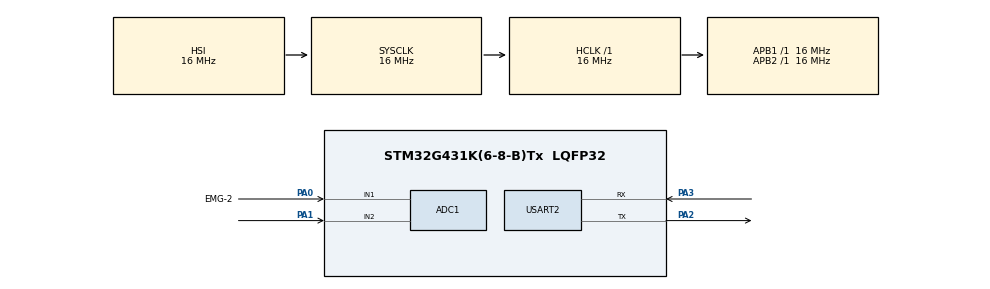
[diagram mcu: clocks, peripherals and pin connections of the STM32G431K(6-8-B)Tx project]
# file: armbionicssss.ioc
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ADC1.Channel-0\#ChannelRegularConversion=ADC_CHANNEL_1
ADC1.Channel-1\#ChannelRegularConversion=ADC_CHANNEL_2
ADC1.ContinuousConvMode=DISABLE
ADC1.DMAContinuousRequests=ENABLE
ADC1.EOCSelection=ADC_EOC_SEQ_CONV
ADC1.ExternalTrigConv=ADC_EXTERNALTRIG_T1_TRGO
ADC1.NbrOfConversion=2
ADC1.NbrOfConversionFlag=1
ADC1.OffsetNumber-0\#ChannelRegularConversion=ADC_OFFSET_NONE
ADC1.OffsetNumber-1\#ChannelRegularConversion=ADC_OFFSET_NONE
ADC1.Overrun=ADC_OVR_DATA_OVERWRITTEN
ADC1.Rank-0\#ChannelRegularConversion=1
ADC1.Rank-1\#ChannelRegularConversion=2
ADC1.SamplingTime-0\#ChannelRegularConversion=ADC_SAMPLETIME_6CYCLES_5
ADC1.SamplingTime-1\#ChannelRegularConversion=ADC_SAMPLETIME_6CYCLES_5
ADC1.master=1
Dma.ADC1.0.Direction=DMA_PERIPH_TO_MEMORY
Dma.ADC1.0.EventEnable=DISABLE
Dma.ADC1.0.Instance=DMA1_Channel1
Dma.ADC1.0.MemDataAlignment=DMA_MDATAALIGN_WORD
Dma.ADC1.0.MemInc=DMA_MINC_ENABLE
Dma.ADC1.0.Mode=DMA_CIRCULAR
Dma.ADC1.0.PeriphDataAlignment=DMA_PDATAALIGN_WORD
Dma.ADC1.0.PeriphInc=DMA_PINC_DISABLE
Dma.ADC1.0.Polarity=HAL_DMAMUX_REQ_GEN_RISING
Dma.ADC1.0.Priority=DMA_PRIORITY_LOW
Dma.ADC1.0.RequestNumber=1
Dma.ADC1.0.SignalID=NONE
Dma.ADC1.0.SyncEnable=DISABLE
Dma.ADC1.0.SyncPolarity=HAL_DMAMUX_SYNC_NO_EVENT
Dma.ADC1.0.SyncRequestNumber=1
Dma.ADC1.0.SyncSignalID=NONE
Dma.Request0=ADC1
Mcu.Family=STM32G4
Mcu.Name=STM32G431K(6-8-B)Tx
Mcu.Package=LQFP32
NVIC.ADC1_2_IRQn=true\:0\:0\:false\:false\:true\:true\:true\:true
NVIC.DMA1_Channel1_IRQn=true\:0\:0\:false\:false\:true\:false\:true\:true
NVIC.PriorityGroup=NVIC_PRIORITYGROUP_4
NVIC.TIM1_TRG_COM_TIM17_IRQn=true\:0\:0\:false\:false\:true\:true\:true\:true
NVIC.TIM1_UP_TIM16_IRQn=true\:0\:0\:false\:false\:true\:true\:true\:true
PA0.GPIO_Label=EMG-2
PA0.GPIO_Pd=GPIO_PULLDOWN
PA0.Mode=IN1-Single-Ended
PA0.Signal=ADC1_IN1
PA1.GPIO_Pd=GPIO_PULLDOWN
PA1.Mode=IN2-Single-Ended
PA1.Signal=ADC1_IN2
PA13.Mode=Trace_Asynchronous_SW
PA13.Signal=SYS_JTMS-SWDIO
PA14.Mode=Trace_Asynchronous_SW
PA14.Signal=SYS_JTCK-SWCLK
PA2.Mode=Asynchronous
PA2.Signal=USART2_TX
PA3.Mode=Asynchronous
PA3.Signal=USART2_RX
PB3.Mode=Trace_Asynchronous_SW
PB3.Signal=SYS_JTDO-SWO
ProjectManager.HeapSize=0x200
ProjectManager.StackSize=0x400
ProjectManager.TargetToolchain=CMake
RCC.AHBFreq_Value=16000000
RCC.APB1Freq_Value=16000000
RCC.APB1TimFreq_Value=16000000
RCC.APB2Freq_Value=16000000
RCC.APB2TimFreq_Value=16000000
RCC.CortexFreq_Value=16000000
RCC.EXTERNAL_CLOCK_VALUE=12288000
RCC.HCLKFreq_Value=16000000
RCC.HSE_VALUE=8000000
RCC.HSI48_VALUE=48000000
RCC.HSI_VALUE=16000000
RCC.LSE_VALUE=32768
RCC.SYSCLKFreq_VALUE=16000000
RCC.USBFreq_Value=64000000
RCC.VCOOutputFreq_Value=128000000
TIM1.PeriodNoDither=9999
TIM1.Prescaler=159
TIM1.TIM_MasterOutputTrigger=TIM_TRGO_UPDATE
TIM1.TIM_MasterOutputTrigger2=TIM_TRGO2_UPDATE
USART2.VirtualMode-Asynchronous=VM_ASYNC
VP_SYS_VS_DBSignals.Mode=DisableDeadBatterySignals
VP_TIM1_VS_ClockSourceINT.Mode=Internal
board=custom

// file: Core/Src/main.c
/* USER CODE BEGIN Header */
/**
  ******************************************************************************
  * @file           : main.c
  * @brief          : Main program body
  ******************************************************************************
  * @attention
  *
  * Copyright (c) 2026 STMicroelectronics.
  * All rights reserved.
  *
  * This software is licensed under terms that can be found in the LICENSE file
  * in the root directory of this software component.
  * If no LICENSE file comes with this software, it is provided AS-IS.
  *
  ******************************************************************************
  */
/* USER CODE END Header */
#include "main.h"
#include <stdint.h>
#include <stdio.h>
#include <string.h>

ADC_HandleTypeDef hadc1;
DMA_HandleTypeDef hdma_adc1;

TIM_HandleTypeDef htim1;

UART_HandleTypeDef huart2;

void SystemClock_Config(void);
static void MX_GPIO_Init(void);
static void MX_DMA_Init(void);
static void MX_ADC1_Init(void);
static void MX_TIM1_Init(void);
static void MX_USART2_UART_Init(void);
void uart_call(void);

/* USER CODE BEGIN 0 */
#define ADC_DMA_BUFFER_SIZE 2
uint32_t adc_dma_buffer[ADC_DMA_BUFFER_SIZE];
uint8_t uart_buffer[4];

/* USER CODE END 0 */

void uart_call(void)
{
    uint32_t value = adc_dma_buffer[0];

    uart_buffer[0] = (value >> 24) & 0xFF;
    uart_buffer[1] = (value >> 16) & 0xFF;
    uart_buffer[2] = (value >> 8) & 0xFF;
    uart_buffer[3] = value & 0xFF;

    char msg[50];

    sprintf(msg,"ADC: %08lX\r\n", value);

    HAL_UART_Transmit(&huart2,(uint8_t*)msg,strlen(msg),1000);
}

int main(void)
{

  /* MCU Configuration--------------------------------------------------------*/

  /* Reset of all peripherals, Initializes the Flash interface and the Systick. */
  HAL_Init();

  /* Configure the system clock */
  SystemClock_Config();

  /* Initialize all configured peripherals */
  MX_GPIO_Init();
  MX_DMA_Init();
  MX_ADC1_Init();
  MX_TIM1_Init();
  MX_USART2_UART_Init();

  /* Infinite loop */
  /* USER CODE BEGIN WHILE */
  HAL_TIM_Base_Start_IT( &htim1);

 // HAL_TIM_PWM_Start(&htim16, TIM_CHANNEL_1);
  HAL_ADC_Start_DMA(&hadc1, adc_dma_buffer, ADC_DMA_BUFFER_SIZE);

  while (1)
{
    uart_call();
    HAL_Delay(1000);
}
  /* USER CODE END 3 */
}

void SystemClock_Config(void)
{
  RCC_OscInitTypeDef RCC_OscInitStruct = {0};
  RCC_ClkInitTypeDef RCC_ClkInitStruct = {0};

  /** Configure the main internal regulator output voltage
  */
  HAL_PWREx_ControlVoltageScaling(PWR_REGULATOR_VOLTAGE_SCALE1);

  /** Initializes the RCC Oscillators according to the specified parameters
  * in the RCC_OscInitTypeDef structure.
  */
  RCC_OscInitStruct.OscillatorType = RCC_OSCILLATORTYPE_HSI;
  RCC_OscInitStruct.HSIState = RCC_HSI_ON;
  RCC_OscInitStruct.HSICalibrationValue = RCC_HSICALIBRATION_DEFAULT;
  RCC_OscInitStruct.PLL.PLLState = RCC_PLL_NONE;
  if (HAL_RCC_OscConfig(&RCC_OscInitStruct) != HAL_OK)
  {
    Error_Handler();
  }

  /** Initializes the CPU, AHB and APB buses clocks
  */
  RCC_ClkInitStruct.ClockType = RCC_CLOCKTYPE_HCLK|RCC_CLOCKTYPE_SYSCLK
                              |RCC_CLOCKTYPE_PCLK1|RCC_CLOCKTYPE_PCLK2;
  RCC_ClkInitStruct.SYSCLKSource = RCC_SYSCLKSOURCE_HSI;
  RCC_ClkInitStruct.AHBCLKDivider = RCC_SYSCLK_DIV1;
  RCC_ClkInitStruct.APB1CLKDivider = RCC_HCLK_DIV1;
  RCC_ClkInitStruct.APB2CLKDivider = RCC_HCLK_DIV1;

  if (HAL_RCC_ClockConfig(&RCC_ClkInitStruct, FLASH_LATENCY_0) != HAL_OK)
  {
    Error_Handler();
  }
}

static void MX_ADC1_Init(void)
{

  ADC_MultiModeTypeDef multimode = {0};
  ADC_ChannelConfTypeDef sConfig = {0};

  /** Common config
  */
  hadc1.Instance = ADC1;
  hadc1.Init.ClockPrescaler = ADC_CLOCK_SYNC_PCLK_DIV2;
  hadc1.Init.Resolution = ADC_RESOLUTION_12B;
  hadc1.Init.DataAlign = ADC_DATAALIGN_RIGHT;
  hadc1.Init.GainCompensation = 0;
  hadc1.Init.ScanConvMode = ADC_SCAN_ENABLE;
  hadc1.Init.EOCSelection = ADC_EOC_SEQ_CONV;
  hadc1.Init.LowPowerAutoWait = DISABLE;
  hadc1.Init.ContinuousConvMode = DISABLE;
  hadc1.Init.NbrOfConversion = 2;
  hadc1.Init.DiscontinuousConvMode = DISABLE;
  hadc1.Init.ExternalTrigConv = ADC_EXTERNALTRIG_T1_TRGO;
  hadc1.Init.ExternalTrigConvEdge = ADC_EXTERNALTRIGCONVEDGE_RISING;
  hadc1.Init.DMAContinuousRequests = ENABLE;
  hadc1.Init.Overrun = ADC_OVR_DATA_OVERWRITTEN;
  hadc1.Init.OversamplingMode = DISABLE;
  if (HAL_ADC_Init(&hadc1) != HAL_OK)
  {
    Error_Handler();
  }

  /** Configure the ADC multi-mode
  */
  multimode.Mode = ADC_MODE_INDEPENDENT;
  if (HAL_ADCEx_MultiModeConfigChannel(&hadc1, &multimode) != HAL_OK)
  {
    Error_Handler();
  }

  /** Configure Regular Channel
  */
  sConfig.Channel = ADC_CHANNEL_1;
  sConfig.Rank = ADC_REGULAR_RANK_1;
  sConfig.SamplingTime = ADC_SAMPLETIME_6CYCLES_5;
  sConfig.SingleDiff = ADC_SINGLE_ENDED;
  sConfig.OffsetNumber = ADC_OFFSET_NONE;
  sConfig.Offset = 0;
  if (HAL_ADC_ConfigChannel(&hadc1, &sConfig) != HAL_OK)
  {
    Error_Handler();
  }

  /** Configure Regular Channel
  */
  sConfig.Channel = ADC_CHANNEL_2;
  sConfig.Rank = ADC_REGULAR_RANK_2;
  if (HAL_ADC_ConfigChannel(&hadc1, &sConfig) != HAL_OK)
  {
    Error_Handler();
  }

}

static void MX_TIM1_Init(void)
{

  TIM_ClockConfigTypeDef sClockSourceConfig = {0};
  TIM_MasterConfigTypeDef sMasterConfig = {0};

  htim1.Instance = TIM1;
  htim1.Init.Prescaler = 159;
  htim1.Init.CounterMode = TIM_COUNTERMODE_UP;
  htim1.Init.Period = 9999;
  htim1.Init.ClockDivision = TIM_CLOCKDIVISION_DIV1;
  htim1.Init.RepetitionCounter = 0;
  htim1.Init.AutoReloadPreload = TIM_AUTORELOAD_PRELOAD_DISABLE;
  if (HAL_TIM_Base_Init(&htim1) != HAL_OK)
  {
    Error_Handler();
  }
  sClockSourceConfig.ClockSource = TIM_CLOCKSOURCE_INTERNAL;
  if (HAL_TIM_ConfigClockSource(&htim1, &sClockSourceConfig) != HAL_OK)
  {
    Error_Handler();
  }
  sMasterConfig.MasterOutputTrigger = TIM_TRGO_UPDATE;
  sMasterConfig.MasterOutputTrigger2 = TIM_TRGO2_UPDATE;
  sMasterConfig.MasterSlaveMode = TIM_MASTERSLAVEMODE_DISABLE;
  if (HAL_TIMEx_MasterConfigSynchronization(&htim1, &sMasterConfig) != HAL_OK)
  {
    Error_Handler();
  }

}

static void MX_USART2_UART_Init(void)
{

  huart2.Instance = USART2;
  huart2.Init.BaudRate = 115200;
  huart2.Init.WordLength = UART_WORDLENGTH_8B;
  huart2.Init.StopBits = UART_STOPBITS_1;
  huart2.Init.Parity = UART_PARITY_NONE;
  huart2.Init.Mode = UART_MODE_TX_RX;
  huart2.Init.HwFlowCtl = UART_HWCONTROL_NONE;
  huart2.Init.OverSampling = UART_OVERSAMPLING_16;
  huart2.Init.OneBitSampling = UART_ONE_BIT_SAMPLE_DISABLE;
  huart2.Init.ClockPrescaler = UART_PRESCALER_DIV1;
  huart2.AdvancedInit.AdvFeatureInit = UART_ADVFEATURE_NO_INIT;
  if (HAL_UART_Init(&huart2) != HAL_OK)
  {
    Error_Handler();
  }
  if (HAL_UARTEx_SetTxFifoThreshold(&huart2, UART_TXFIFO_THRESHOLD_1_8) != HAL_OK)
  {
    Error_Handler();
  }
  if (HAL_UARTEx_SetRxFifoThreshold(&huart2, UART_RXFIFO_THRESHOLD_1_8) != HAL_OK)
  {
    Error_Handler();
  }
  if (HAL_UARTEx_DisableFifoMode(&huart2) != HAL_OK)
  {
    Error_Handler();
  }

}

static void MX_DMA_Init(void)
{

  /* DMA controller clock enable */
  __HAL_RCC_DMAMUX1_CLK_ENABLE();
  __HAL_RCC_DMA1_CLK_ENABLE();

  /* DMA interrupt init */
  /* DMA1_Channel1_IRQn interrupt configuration */
  HAL_NVIC_SetPriority(DMA1_Channel1_IRQn, 0, 0);
  HAL_NVIC_EnableIRQ(DMA1_Channel1_IRQn);

}

static void MX_GPIO_Init(void)
{

  /* GPIO Ports Clock Enable */
  __HAL_RCC_GPIOA_CLK_ENABLE();
  __HAL_RCC_GPIOB_CLK_ENABLE();

}

void Error_Handler(void)
{
  __disable_irq();
  while (1)
  {
  }
}
